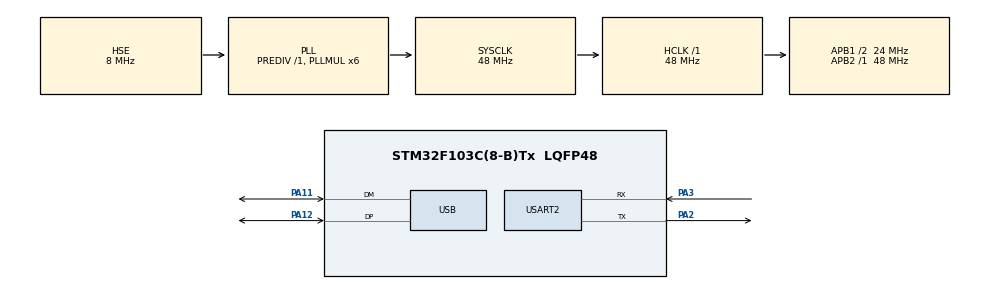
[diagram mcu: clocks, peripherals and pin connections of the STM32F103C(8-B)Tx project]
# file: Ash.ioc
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Mcu.Family=STM32F1
Mcu.Name=STM32F103C(8-B)Tx
Mcu.Package=LQFP48
NVIC.PriorityGroup=NVIC_PRIORITYGROUP_4
PA11.Mode=Device
PA11.Signal=USB_DM
PA12.Mode=Device
PA12.Signal=USB_DP
PA2.Mode=Asynchronous
PA2.Signal=USART2_TX
PA3.Mode=Asynchronous
PA3.Signal=USART2_RX
PD0-OSC_IN.Mode=HSE-External-Oscillator
PD0-OSC_IN.Signal=RCC_OSC_IN
PD1-OSC_OUT.Mode=HSE-External-Oscillator
PD1-OSC_OUT.Signal=RCC_OSC_OUT
ProjectManager.HeapSize=0x200
ProjectManager.StackSize=0x400
ProjectManager.TargetToolchain=STM32CubeIDE
RCC.AHBFreq_Value=48000000
RCC.APB1CLKDivider=RCC_HCLK_DIV2
RCC.APB1Freq_Value=24000000
RCC.APB1TimFreq_Value=48000000
RCC.APB2Freq_Value=48000000
RCC.APB2TimFreq_Value=48000000
RCC.HCLKFreq_Value=48000000
RCC.PLLMUL=RCC_PLL_MUL6
RCC.SYSCLKFreq_VALUE=48000000
RCC.SYSCLKSource=RCC_SYSCLKSOURCE_PLLCLK
RCC.USBFreq_Value=48000000
USART2.VirtualMode=VM_ASYNC
VP_SYS_VS_ND.Mode=No_Debug
board=custom

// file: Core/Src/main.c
/* USER CODE BEGIN Header */
/**
  ******************************************************************************
  * @file           : main.c
  * @brief          : Main program body
  ******************************************************************************
  * @attention
  *
  * Copyright (c) 2025 STMicroelectronics.
  * All rights reserved.
  *
  * This software is licensed under terms that can be found in the LICENSE file
  * in the root directory of this software component.
  * If no LICENSE file comes with this software, it is provided AS-IS.
  *
  ******************************************************************************
  */
/* USER CODE END Header */
#include "main.h"

UART_HandleTypeDef huart2;

PCD_HandleTypeDef hpcd_USB_FS;

void SystemClock_Config(void);
static void MX_GPIO_Init(void);
static void MX_USART2_UART_Init(void);
static void MX_USB_PCD_Init(void);

int main(void)
{

  /* MCU Configuration--------------------------------------------------------*/

  /* Reset of all peripherals, Initializes the Flash interface and the Systick. */
  HAL_Init();

  /* Configure the system clock */
  SystemClock_Config();

  /* Initialize all configured peripherals */
  MX_GPIO_Init();
  MX_USART2_UART_Init();
  MX_USB_PCD_Init();

  /* Infinite loop */
  /* USER CODE BEGIN WHILE */
  while (1)
  {
      // Check if USB is connected, and enter sleep mode if not
      if (hpcd_USB_FS.State != HAL_PCD_STATE_CONNECTED) {
          // Enter sleep mode if USB is not connected
    	  uint8_t num = 69;
    	  UART_Send_To_First_MCU(num);
          HAL_PWR_EnterSLEEPMode(PWR_MAINREGULATOR_ON, PWR_SLEEPENTRY_WFI);

      } else {
          // USB is connected, proceed with UART data handling
          UART_Receive_Data();
      }
    /* USER CODE END WHILE */

  }
}

void SystemClock_Config(void)
{
  RCC_OscInitTypeDef RCC_OscInitStruct = {0};
  RCC_ClkInitTypeDef RCC_ClkInitStruct = {0};
  RCC_PeriphCLKInitTypeDef PeriphClkInit = {0};

  /** Initializes the RCC Oscillators according to the specified parameters
  * in the RCC_OscInitTypeDef structure.
  */
  RCC_OscInitStruct.OscillatorType = RCC_OSCILLATORTYPE_HSE;
  RCC_OscInitStruct.HSEState = RCC_HSE_ON;
  RCC_OscInitStruct.HSEPredivValue = RCC_HSE_PREDIV_DIV1;
  RCC_OscInitStruct.HSIState = RCC_HSI_ON;
  RCC_OscInitStruct.PLL.PLLState = RCC_PLL_ON;
  RCC_OscInitStruct.PLL.PLLSource = RCC_PLLSOURCE_HSE;
  RCC_OscInitStruct.PLL.PLLMUL = RCC_PLL_MUL6;
  if (HAL_RCC_OscConfig(&RCC_OscInitStruct) != HAL_OK)
  {
    Error_Handler();
  }

  /** Initializes the CPU, AHB and APB buses clocks
  */
  RCC_ClkInitStruct.ClockType = RCC_CLOCKTYPE_HCLK|RCC_CLOCKTYPE_SYSCLK
                              |RCC_CLOCKTYPE_PCLK1|RCC_CLOCKTYPE_PCLK2;
  RCC_ClkInitStruct.SYSCLKSource = RCC_SYSCLKSOURCE_PLLCLK;
  RCC_ClkInitStruct.AHBCLKDivider = RCC_SYSCLK_DIV1;
  RCC_ClkInitStruct.APB1CLKDivider = RCC_HCLK_DIV2;
  RCC_ClkInitStruct.APB2CLKDivider = RCC_HCLK_DIV1;

  if (HAL_RCC_ClockConfig(&RCC_ClkInitStruct, FLASH_LATENCY_1) != HAL_OK)
  {
    Error_Handler();
  }
  PeriphClkInit.PeriphClockSelection = RCC_PERIPHCLK_USB;
  PeriphClkInit.UsbClockSelection = RCC_USBCLKSOURCE_PLL;
  if (HAL_RCCEx_PeriphCLKConfig(&PeriphClkInit) != HAL_OK)
  {
    Error_Handler();
  }
}

static void MX_USART2_UART_Init(void)
{

  huart2.Instance = USART2;
  huart2.Init.BaudRate = 8600;
  huart2.Init.WordLength = UART_WORDLENGTH_8B;
  huart2.Init.StopBits = UART_STOPBITS_1;
  huart2.Init.Parity = UART_PARITY_NONE;
  huart2.Init.Mode = UART_MODE_TX_RX;
  huart2.Init.HwFlowCtl = UART_HWCONTROL_NONE;
  huart2.Init.OverSampling = UART_OVERSAMPLING_16;
  if (HAL_UART_Init(&huart2) != HAL_OK)
  {
    Error_Handler();
  }

}

static void MX_USB_PCD_Init(void)
{

  hpcd_USB_FS.Instance = USB;
  hpcd_USB_FS.Init.dev_endpoints = 8;
  hpcd_USB_FS.Init.speed = PCD_SPEED_FULL;
  hpcd_USB_FS.Init.low_power_enable = ENABLE;
  hpcd_USB_FS.Init.lpm_enable = ENABLE;
  hpcd_USB_FS.Init.battery_charging_enable = DISABLE;
  if (HAL_PCD_Init(&hpcd_USB_FS) != HAL_OK)
  {
    Error_Handler();
  }
}

static void MX_GPIO_Init(void)
{

  /* GPIO Ports Clock Enable */
  __HAL_RCC_GPIOD_CLK_ENABLE();
  __HAL_RCC_GPIOA_CLK_ENABLE();

}

void Send_HID_Key(uint8_t key) {
    uint8_t HID_report[8] = {0};  // HID report with a size of 8 bytes

    // Set the key in the HID report (the key code for 'W', 'A', 'S', 'D')
    HID_report[2] = key;  // Using byte 2 to represent the key pressed

    // Send the HID report (press key)
    if (hpcd_USB_FS.State == HAL_PCD_STATE_READY)
    {
    	USBD_HID_SendReport(&hUsbDeviceFS, HID_report, sizeof(HID_report));
    }

    // Delay to simulate key press duration
    HAL_Delay(100);

    // Release the key (send 0)
    HID_report[2] = 0;
    if (hpcd_USB_FS.State == HAL_PCD_STATE_READY)
    {
    	USBD_HID_SendReport(&hUsbDeviceFS, HID_report, sizeof(HID_report));
    }
}

void UART_Receive_Data(void) {
    uint8_t received_data;

    if (HAL_UART_Receive(&huart2, &received_data, 1, 100) == HAL_OK) {
        if (received_data == 'W') {
            Send_HID_Key(0x11);
        }
        else if (received_data == 'A') {
            Send_HID_Key(0x04);
        }
        else if (received_data == 'S') {
            Send_HID_Key(0x1F);
        }
        else if (received_data == 'D') {
            Send_HID_Key(0x05);
        }
    }
}

void UART_Send_To_First_MCU(uint8_t data){
    HAL_UART_Transmit(&huart2, (uint8_t *)&data, 1, HAL_MAX_DELAY);
}
void Error_Handler(void)
{
  __disable_irq();
  while (1)
  {
  }
}
